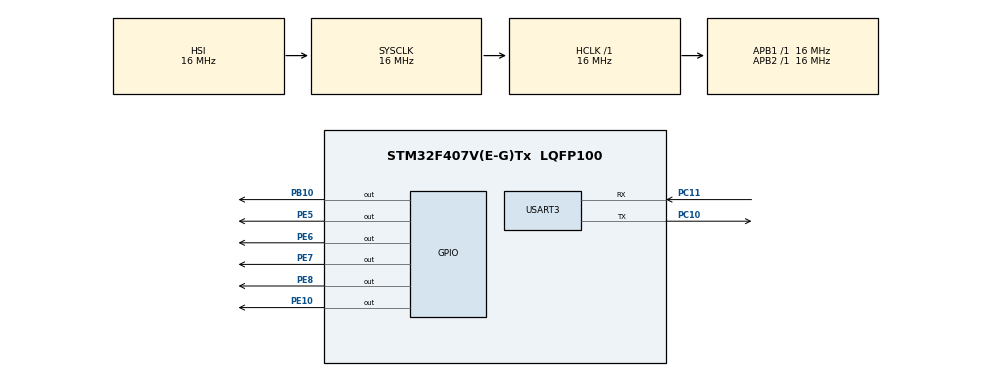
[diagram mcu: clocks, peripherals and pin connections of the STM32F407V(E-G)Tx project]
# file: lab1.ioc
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Mcu.Family=STM32F4
Mcu.Name=STM32F407V(E-G)Tx
Mcu.Package=LQFP100
NVIC.PriorityGroup=NVIC_PRIORITYGROUP_4
PA13.Signal=SYS_JTMS-SWDIO
PA14.Signal=SYS_JTCK-SWCLK
PB10.Signal=GPIO_Output
PC10.Mode=Asynchronous
PC10.Signal=USART3_TX
PC11.Mode=Asynchronous
PC11.Signal=USART3_RX
PE10.Signal=GPIO_Output
PE5.Signal=GPIO_Output
PE6.Signal=GPIO_Output
PE7.Signal=GPIO_Output
PE8.Signal=GPIO_Output
ProjectManager.HeapSize=0x200
ProjectManager.StackSize=0x400
ProjectManager.TargetToolchain=STM32CubeIDE
RCC.AHBFreq_Value=16000000
RCC.APB1Freq_Value=16000000
RCC.APB2Freq_Value=16000000
RCC.CortexFreq_Value=16000000
RCC.HSE_VALUE=25000000
RCC.HSI_VALUE=16000000
RCC.LSE_VALUE=32768
RCC.SYSCLKFreq_VALUE=16000000
RCC.VCOOutputFreq_Value=192000000
USART3.VirtualMode=VM_ASYNC
board=custom

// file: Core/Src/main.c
/* USER CODE BEGIN Header */
/**
  ******************************************************************************
  * @file           : main.c
  * @brief          : Main program body
  ******************************************************************************
  * @attention
  *
  * Copyright (c) 2022 STMicroelectronics.
  * All rights reserved.
  *
  * This software is licensed under terms that can be found in the LICENSE file
  * in the root directory of this software component.
  * If no LICENSE file comes with this software, it is provided AS-IS.
  *
  ******************************************************************************
  */
/* USER CODE END Header */
#include "main.h"

/* USER CODE BEGIN Includes */
#include "oled.h"
/* USER CODE END Includes */

 UART_HandleTypeDef huart3;

void SystemClock_Config(void);
static void MX_GPIO_Init(void);
static void MX_USART3_UART_Init(void);

int main(void)
{
  /* USER CODE BEGIN 1 */
uint8_t *oled_buf;
  /* USER CODE END 1 */

  /* MCU Configuration--------------------------------------------------------*/

  /* Reset of all peripherals, Initializes the Flash interface and the Systick. */
  HAL_Init();

  /* Configure the system clock */
  SystemClock_Config();

  /* Initialize all configured peripherals */
  MX_GPIO_Init();
  MX_USART3_UART_Init();
  /* USER CODE BEGIN 2 */
OLED_Init();
OLED_ShowString(0,5,"WTF Bro");
OLED_Refresh_Gram();
HAL_Delay(2000);
OLED_Clear();
  /* USER CODE END 2 */

  /* Infinite loop */
  /* USER CODE BEGIN WHILE */
  uint8_t sbuf[] = "Hello world";
  while (1)
  {
	  HAL_GPIO_TogglePin(GPIOE,GPIO_PIN_10);
	  //HAL_GPIO_TogglePin(GPIOB,GPIO_PIN_10);
	  HAL_Delay(100);
	  HAL_UART_Transmit(&huart3,sbuf,sizeof(sbuf), HAL_MAX_DELAY);
    /* USER CODE END WHILE */

  }
}

void SystemClock_Config(void)
{
  RCC_OscInitTypeDef RCC_OscInitStruct = {0};
  RCC_ClkInitTypeDef RCC_ClkInitStruct = {0};

  /** Configure the main internal regulator output voltage
  */
  __HAL_RCC_PWR_CLK_ENABLE();
  __HAL_PWR_VOLTAGESCALING_CONFIG(PWR_REGULATOR_VOLTAGE_SCALE1);

  /** Initializes the RCC Oscillators according to the specified parameters
  * in the RCC_OscInitTypeDef structure.
  */
  RCC_OscInitStruct.OscillatorType = RCC_OSCILLATORTYPE_HSI;
  RCC_OscInitStruct.HSIState = RCC_HSI_ON;
  RCC_OscInitStruct.HSICalibrationValue = RCC_HSICALIBRATION_DEFAULT;
  RCC_OscInitStruct.PLL.PLLState = RCC_PLL_NONE;
  if (HAL_RCC_OscConfig(&RCC_OscInitStruct) != HAL_OK)
  {
    Error_Handler();
  }

  /** Initializes the CPU, AHB and APB buses clocks
  */
  RCC_ClkInitStruct.ClockType = RCC_CLOCKTYPE_HCLK|RCC_CLOCKTYPE_SYSCLK
                              |RCC_CLOCKTYPE_PCLK1|RCC_CLOCKTYPE_PCLK2;
  RCC_ClkInitStruct.SYSCLKSource = RCC_SYSCLKSOURCE_HSI;
  RCC_ClkInitStruct.AHBCLKDivider = RCC_SYSCLK_DIV1;
  RCC_ClkInitStruct.APB1CLKDivider = RCC_HCLK_DIV1;
  RCC_ClkInitStruct.APB2CLKDivider = RCC_HCLK_DIV1;

  if (HAL_RCC_ClockConfig(&RCC_ClkInitStruct, FLASH_LATENCY_0) != HAL_OK)
  {
    Error_Handler();
  }
}

static void MX_USART3_UART_Init(void)
{

  huart3.Instance = USART3;
  huart3.Init.BaudRate = 115200;
  huart3.Init.WordLength = UART_WORDLENGTH_8B;
  huart3.Init.StopBits = UART_STOPBITS_1;
  huart3.Init.Parity = UART_PARITY_NONE;
  huart3.Init.Mode = UART_MODE_TX_RX;
  huart3.Init.HwFlowCtl = UART_HWCONTROL_NONE;
  huart3.Init.OverSampling = UART_OVERSAMPLING_16;
  if (HAL_UART_Init(&huart3) != HAL_OK)
  {
    Error_Handler();
  }

}

static void MX_GPIO_Init(void)
{
  GPIO_InitTypeDef GPIO_InitStruct = {0};

  /* GPIO Ports Clock Enable */
  __HAL_RCC_GPIOE_CLK_ENABLE();
  __HAL_RCC_GPIOB_CLK_ENABLE();
  __HAL_RCC_GPIOA_CLK_ENABLE();
  __HAL_RCC_GPIOC_CLK_ENABLE();

  /*Configure GPIO pin Output Level */
  HAL_GPIO_WritePin(GPIOE, GPIO_PIN_5|GPIO_PIN_6|GPIO_PIN_7|GPIO_PIN_8
                          |GPIO_PIN_10, GPIO_PIN_RESET);

  /*Configure GPIO pin Output Level */
  HAL_GPIO_WritePin(GPIOB, GPIO_PIN_10, GPIO_PIN_RESET);

  /*Configure GPIO pins : PE5 PE6 PE7 PE8
                           PE10 */
  GPIO_InitStruct.Pin = GPIO_PIN_5|GPIO_PIN_6|GPIO_PIN_7|GPIO_PIN_8
                          |GPIO_PIN_10;
  GPIO_InitStruct.Mode = GPIO_MODE_OUTPUT_PP;
  GPIO_InitStruct.Pull = GPIO_NOPULL;
  GPIO_InitStruct.Speed = GPIO_SPEED_FREQ_LOW;
  HAL_GPIO_Init(GPIOE, &GPIO_InitStruct);

  /*Configure GPIO pin : PB10 */
  GPIO_InitStruct.Pin = GPIO_PIN_10;
  GPIO_InitStruct.Mode = GPIO_MODE_OUTPUT_PP;
  GPIO_InitStruct.Pull = GPIO_NOPULL;
  GPIO_InitStruct.Speed = GPIO_SPEED_FREQ_LOW;
  HAL_GPIO_Init(GPIOB, &GPIO_InitStruct);

}

void Error_Handler(void)
{
  __disable_irq();
  while (1)
  {
  }
}
